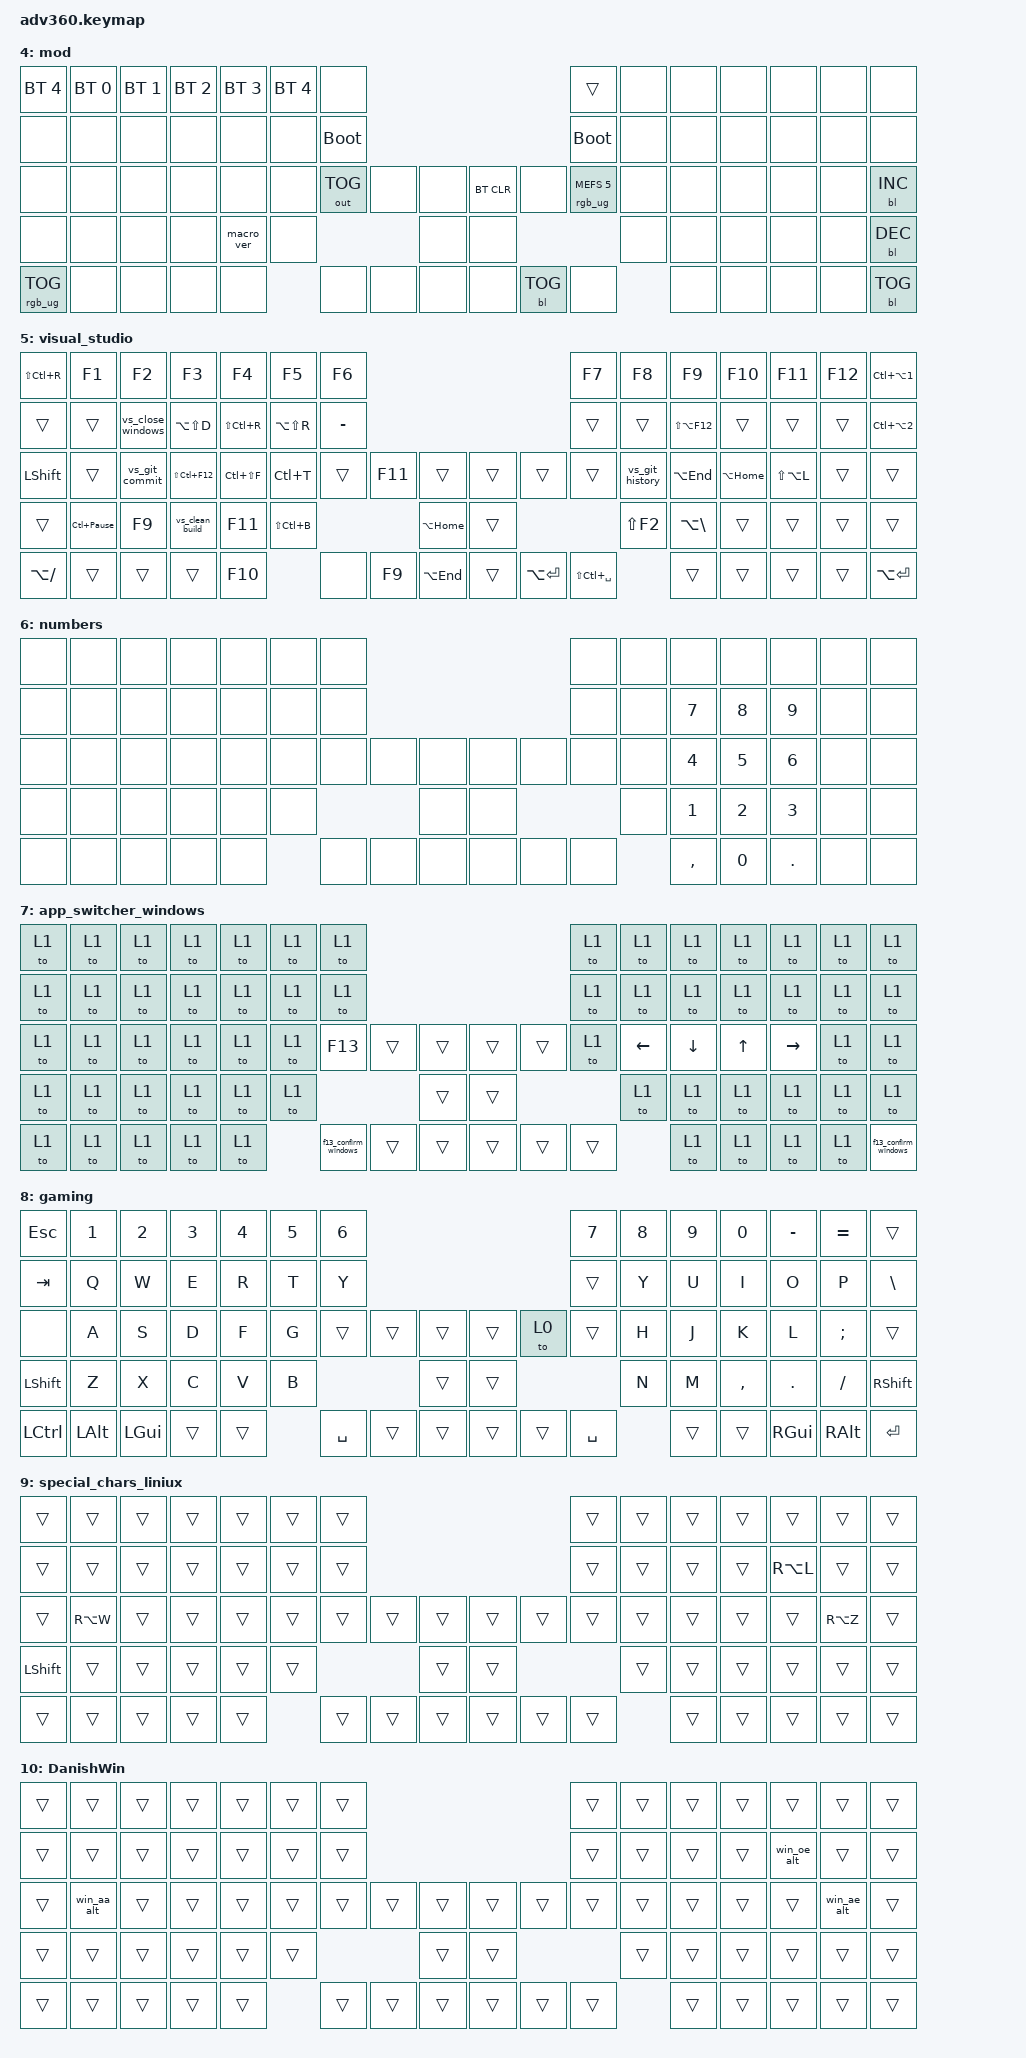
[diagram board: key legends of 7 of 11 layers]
#include <dt-bindings/zmk/mouse.h>
#include <behaviors.dtsi>
#include <dt-bindings/zmk/backlight.h>
#include <dt-bindings/zmk/bt.h>
#include <dt-bindings/zmk/keys.h>
#include <dt-bindings/zmk/outputs.h>
#include <dt-bindings/zmk/pointing.h>
#include <dt-bindings/zmk/rgb.h>

&mt { tapping-term-ms = <225>; };

/ {
    behaviors {
        #include "macros.dtsi"
      #include "version.dtsi"
      #ifndef VERSION_MACRO

        macro_ver: macro_ver {
            compatible = "zmk,behavior-macro";
            label = "macro_version";
            #binding-cells = <0>;
            bindings = <&kp RET>;
        };

        #endif

        as_ht: autoshift_hold_tap {
            compatible = "zmk,behavior-hold-tap";
            label = "AUTOSHIFT_HOLD_TAP";
            #binding-cells = <2>;
            tapping-term-ms = <200>;
            bindings = <&shifted>, <&kp>;

            quick-tap-ms = <175>;
            flavor = "tap-preferred";
        };

        shifted: macro_shifted_kp {
            #binding-cells = <1>;
            label = "MACRO_SHIFTED_KP";
            compatible = "zmk,behavior-macro-one-param";
            bindings =
                <&macro_press>,
                <&kp LSHFT &macro_param_1to1>,
                <&macro_tap>,
                <&kp MACRO_PLACEHOLDER>,
                <&macro_release>,
                <&kp LSHFT>;
        };

        as: autoshift {
            compatible = "zmk,behavior-macro-one-param";
            #binding-cells = <1>;
            label = "AUTOSHIFT_KP";
            bindings =
                <&macro_press>,
                <&macro_param_1to1 &macro_param_1to2 &as_ht MACRO_PLACEHOLDER MACRO_PLACEHOLDER>,
                <&macro_pause_for_release>,
                <&macro_release>,
                <&macro_param_1to1 &macro_param_1to2 &as_ht MACRO_PLACEHOLDER MACRO_PLACEHOLDER>;
        };

        smiley: smiley {
            compatible = "zmk,behavior-macro";
            #binding-cells = <0>;
            bindings = <&kp COLON &kp MINUS &kp RPAR &kp LC(Z) &kp SPACE &kp LC(Z)>;
            label = "SMILEY";
        };

        vs_close_windows: vs_close_windows {
            compatible = "zmk,behavior-macro";
            #binding-cells = <0>;
            bindings = <&kp LA(W) &kp L>;
            label = "VS_CLOSE_WINDOWS";
        };

        vs_git_commit: vs_git_commit {
            compatible = "zmk,behavior-macro";
            #binding-cells = <0>;
            bindings = <&kp LA(G) &kp C>;
            label = "VS_GIT_COMMIT";
        };

        vs_clean_build: vs_clean_build {
            compatible = "zmk,behavior-macro";
            #binding-cells = <0>;
            bindings = <&kp LA(B) &kp C>;
            label = "VS_CLEAN_BUILD";
        };

        vs_git_history: vs_git_history {
            compatible = "zmk,behavior-macro";
            #binding-cells = <0>;
            bindings = <&kp LA(G) &kp H>;
            label = "VS_GIT_HISTORY";
        };

        equal_lt: equal_lt {
            compatible = "zmk,behavior-macro";
            #binding-cells = <0>;
            bindings = <&kp EQUAL &kp GREATER_THAN>;
            label = "EQUAL_LT";
        };

        macro_parens: macro_parens {
            compatible = "zmk,behavior-macro";
            #binding-cells = <0>;
            bindings = <&kp LEFT_PARENTHESIS &kp RIGHT_PARENTHESIS &kp LEFT>;
            label = "MACRO_PARENS";
        };

        macro_square: macro_square {
            compatible = "zmk,behavior-macro";
            #binding-cells = <0>;
            bindings = <&kp LEFT_BRACKET &kp RIGHT_BRACKET &kp LEFT>;
            label = "MACRO_SQUARE";
        };

        macro_curly: macro_curly {
            compatible = "zmk,behavior-macro";
            #binding-cells = <0>;
            bindings = <&kp LEFT_BRACE &kp RIGHT_BRACE &kp LEFT>;
            label = "MACRO_CURLY";
        };

        macro_pointy: macro_pointy {
            compatible = "zmk,behavior-macro";
            #binding-cells = <0>;
            bindings = <&kp LESS_THAN &kp GREATER_THAN &kp LEFT>;
            label = "MACRO_POINTY";
        };

        macro_quote_pair: macro_quote_pair {
            compatible = "zmk,behavior-macro";
            #binding-cells = <0>;
            bindings = <&kp DOUBLE_QUOTES &kp DOUBLE_QUOTES &kp LEFT>;
            label = "MACRO_QUOTE_PAIR";
        };

        macro_backtick_pair: macro_backtick_pair {
            compatible = "zmk,behavior-macro";
            #binding-cells = <0>;
            bindings = <&kp GRAVE &kp GRAVE &kp LEFT>;
            label = "MACRO_BACKTICK_PAIR";
        };

        f13_switcher_mac: f13_switcher_mac {
            compatible = "zmk,behavior-macro";
            #binding-cells = <0>;
            bindings = <&kp F13 &to 0>;
            label = "F13_SWITCHER_MAC";
        };

        f13_confirm_mac: confirm_app_switch {
            compatible = "zmk,behavior-macro";
            #binding-cells = <0>;
            bindings = <&kp ENTER &to 0>;
            label = "CONFIRM_APP_SWITCH";
        };

        single_quote_pair: single_quote_pair {
            compatible = "zmk,behavior-macro";
            #binding-cells = <0>;
            bindings = <&kp SQT &kp SQT &kp LEFT>;
            label = "SINGLE_QUOTE_PAIR";
        };

        f13_app_sw_windows: f13_app_sw_windows {
            compatible = "zmk,behavior-macro";
            #binding-cells = <0>;
            bindings = <&kp F13 &to 7>;
            label = "F13_APP_SW_WINDOWS";
        };

        f13_confirm_windows: f13_confirm_windows {
            compatible = "zmk,behavior-macro";
            #binding-cells = <0>;
            bindings = <&kp ENTER &to 1>;
            label = "F13_CONFIRM_WINDOWS";
        };

        windows_oe: windows_oe {
            compatible = "zmk,behavior-macro";
            #binding-cells = <0>;
            bindings = <&kt LEFT_META &kp O &kt LEFT_META>;
            label = "WINDOWS_OE";
        };

        windows_ae: windows_ae {
            compatible = "zmk,behavior-macro";
            #binding-cells = <0>;
            bindings = <&kt LEFT_META &kp SINGLE_QUOTE &kt LEFT_META>;
            label = "WINDOWS_AE";
        };

        windows_aa: windows_aa {
            compatible = "zmk,behavior-macro";
            #binding-cells = <0>;
            bindings = <&kt LEFT_META &kp A &kt LEFT_META>;
            label = "WINDOWS_AA";
        };

        win_aa_alt: win_aa_alt {
            compatible = "zmk,behavior-macro";
            #binding-cells = <0>;
            label = "WIN_AA_ALT";
            bindings =
                <&macro_press>,
                <&kp LALT>,
                <&macro_tap>,
                <&kp KP_N0 &kp KP_N2 &kp KP_N2 &kp KP_N9>,
                <&macro_release>,
                <&kp LALT>;
        };

        win_oe_alt: win_oe_alt {
            compatible = "zmk,behavior-macro";
            #binding-cells = <0>;
            label = "WIN_OE_ALT";
            bindings =
                <&macro_press>,
                <&kp LALT>,
                <&macro_tap>,
                <&kp KP_N0 &kp KP_N2 &kp KP_N4 &kp KP_N8>,
                <&macro_release>,
                <&kp LALT>;
        };

        win_ae_alt: win_ae_alt {
            compatible = "zmk,behavior-macro";
            #binding-cells = <0>;
            label = "WIN_AE_ALT";
            bindings =
                <&macro_press>,
                <&kp LALT>,
                <&macro_tap>,
                <&kp KP_N0 &kp KP_N2 &kp KP_N3 &kp KP_N0>,
                <&macro_release>,
                <&kp LALT>;
        };

        linux_move_window: linux_move_win {
            compatible = "zmk,behavior-macro";
            #binding-cells = <0>;
            bindings =
                <&macro_press>,
                <&kp LGUI &mkp MB1>,
                <&macro_pause_for_release>,
                <&macro_release>,
                <&kp LGUI &mkp MB1>;

            label = "LINUX_MOVE_WIN";
        };

        linux_resize_window: linux_resize_window {
            compatible = "zmk,behavior-macro";
            #binding-cells = <0>;
            bindings =
                <&macro_press>,
                <&kp LGUI &mkp MB2>,
                <&macro_pause_for_release>,
                <&macro_release>,
                <&kp LGUI &mkp MB2>;

            label = "LINUX_RESIZE_WINDOW";
        };

        linux_aa: linux_aa {
            compatible = "zmk,behavior-macro";
            #binding-cells = <0>;
            bindings = <&kp LC(LS(U)) &kp E &kp NUMBER_5 &kp SPACE>;
            label = "LINUX_AA";
        };

        linux_oe: linux_oe {
            compatible = "zmk,behavior-macro";
            #binding-cells = <0>;
            bindings = <&kp LC(LS(U)) &kp F &kp N8 &kp SPACE>;
            label = "LINUX_OE";
        };

        linux_ae: linux_ae {
            compatible = "zmk,behavior-macro";
            #binding-cells = <0>;
            bindings = <&kp LS(LC(U)) &kp E &kp N6 &kp SPACE>;
            label = "LINUX_AE";
        };

        linux_hide_others: linux_hide_others {
            compatible = "zmk,behavior-macro";
            #binding-cells = <0>;
            bindings =
                <&kp LG(D)>,
                <&macro_press>,
                <&kp LALT>,
                <&macro_tap>,
                <&kp TAB>,
                <&macro_release>,
                <&kp LALT>;

            label = "LINUX_HIDE_OTHERS";
        };

        switch_to_windows: switch_to_windows {
            compatible = "zmk,behavior-macro";
            #binding-cells = <0>;
            bindings = <&out OUT_USB &to 1 &bt BT_SEL 4>;
            label = "SWITCH_TO_WINDOWS";
        };

        switch_to_linux_bt: switch_to_linux {
            compatible = "zmk,behavior-macro";
            #binding-cells = <0>;
            bindings = <&out OUT_BLE &to 0 &bt BT_SEL 0>;
            label = "SWITCH_TO_LINUX";
        };

        smiley_linux: smiley_linux {
            compatible = "zmk,behavior-macro";
            #binding-cells = <0>;
            bindings = <&kp COLON &kp MINUS &kp RPAR &kp LC(Z) &kp SPACE>;
            label = "SMILEY_LINUX";
        };

        switch_to_linux_wired: switch_to_linux_wired {
            compatible = "zmk,behavior-macro";
            #binding-cells = <0>;
            bindings = <&out OUT_USB &to 0>;
            label = "SWITCH_TO_LINUX_WIRED";
        };

        shift_caps_words: shift_caps_words {
            compatible = "zmk,behavior-tap-dance";
            label = "SHIFT_CAPS_WORDS";
            #binding-cells = <0>;
            bindings = <&kp LEFT_SHIFT>, <&caps_word>;
        };

        holdtap_tap_preferred: holdtap_tap_preferred {
            compatible = "zmk,behavior-hold-tap";
            label = "HOLDTAP_TAP_PREFERRED";
            bindings = <&kp>, <&kp>;

            #binding-cells = <2>;
            tapping-term-ms = <200>;
            flavor = "tap-preferred";
        };

        holdtap_altgr: holdtap_altgr {
            compatible = "zmk,behavior-hold-tap";
            label = "HOLDTAP_ALTGR";
            bindings = <&kp>, <&kp>;

            #binding-cells = <2>;
            tapping-term-ms = <200>;
            quick-tap-ms = <175>;
            flavor = "balanced";
            hold-trigger-on-release;
            hold-trigger-key-positions = <16 43 47>;
        };

        hml: hml {
            compatible = "zmk,behavior-hold-tap";
            label = "HML";
            bindings = <&kp>, <&kp>;

            #binding-cells = <2>;
            tapping-term-ms = <280>;
            quick-tap-ms = <175>;
            require-prior-idle-ms = <150>;
            flavor = "balanced";
            hold-trigger-on-release;
            hold-trigger-key-positions = <8 9 10 11 12 22 23 24 25 26 40 41 42 43 44 54 55 56 57 58 65 66 69 70 13 27 45 59>;
        };

        hmr: hmr {
            compatible = "zmk,behavior-hold-tap";
            label = "HMR";
            bindings = <&kp>, <&kp>;

            #binding-cells = <2>;
            tapping-term-ms = <280>;
            quick-tap-ms = <175>;
            require-prior-idle-ms = <150>;
            flavor = "balanced";
            hold-trigger-on-release;
            hold-trigger-key-positions = <1 2 3 4 5 15 16 17 18 19 29 30 31 32 33 47 48 49 50 51 65 66 70 69 0 14 28 46>;
        };

        htnr: htnr {
            compatible = "zmk,behavior-hold-tap";
            label = "HTNR";
            bindings = <&mo>, <&kp>;

            #binding-cells = <2>;
            tapping-term-ms = <280>;
            flavor = "balanced";
            hold-trigger-key-positions = <7 8 9 10 11 12 13 21 22 23 24 25 26 27 38 39 40 41 42 43 44 45 54 55 56 57 58 59 69 70 71 72 73 74 75>;
            hold-trigger-on-release;
            quick-tap-ms = <175>;
            require-prior-idle-ms = <150>;
        };

        htnl: htnl {
            compatible = "zmk,behavior-hold-tap";
            label = "HTNL";
            bindings = <&mo>, <&kp>;

            #binding-cells = <2>;
            tapping-term-ms = <280>;
            flavor = "balanced";
            hold-trigger-on-release;
            quick-tap-ms = <175>;
            require-prior-idle-ms = <150>;
            hold-trigger-key-positions = <0 1 2 3 4 5 6 14 15 16 17 18 19 20 28 29 30 31 32 33 34 35 46 47 48 49 50 51 60 61 62 63 64 65 66>;
        };

        holdtap_danish: holdtap_danish {
            compatible = "zmk,behavior-hold-tap";
            label = "HOLDTAP_DANISH";
            bindings = <&kp>, <&kp>;

            #binding-cells = <2>;
            tapping-term-ms = <200>;
            hold-trigger-key-positions = <29 45 25>;
            flavor = "balanced";
        };
    };

    macros {
    };

    keymap {
        compatible = "zmk,keymap";

        Linux {
            label = "Linux";
            bindings = <
&kp GRAVE       &kp N1  &kp N2  &kp N3    &kp N4    &kp N5  &lt 4 NUMBER_6                                                                                      &lt 4 NUMBER_7      &kp NUMBER_8  &kp NUMBER_9                           &kp NUMBER_0                               &kp MINUS  &kp EQUAL      &none
&kp TAB         &kp Q   &kp W   &kp E     &kp R     &kp T   &to 1                                                                                               &kp LG(L)           &kp Y         &kp U                                  &kp I                                      &kp O      &kp P          &kp BACKSLASH
&kp CAPSLOCK    &kp A   &kp S   &kp D     &kp F     &kp G   &kp LG(W)       &kp LS(LA(LCTRL))  &kp LS(LA(LC(LGUI)))      &switch_to_linux_wired  &to 8          &kp LC(LA(DELETE))  &kp H         &kp J                                  &kp K                                      &kp L      &kp SEMICOLON  &kp SQT
&kp LEFT_SHIFT  &kp Z   &kp X   &kp C     &kp V     &kp B                                      &bl BL_TOG                &switch_to_linux_bt                                        &kp N         &kp M                                  &kp COMMA                                  &kp DOT    &kp FSLH       &kp RIGHT_SHIFT
&kp LCTRL       &mo 6   &none   &kp LGUI  &kp LALT          &mo 3           &kp RA(O)          &kp LCMD                  &switch_to_windows      &kp BACKSPACE  &kp SPACE                         &holdtap_altgr RIGHT_ALT LEFT_BRACKET  &holdtap_tap_preferred LGUI RIGHT_BRACKET  &none      &none          &mt RCTRL ENTER
            >;
        };

        windows {
            label = "Windows";
            bindings = <
&kp GRAVE       &kp N1  &kp N2  &kp N3    &kp N4        &kp N5  &lt 4 NUMBER_6                                                                                           &lt 4 NUMBER_7      &kp NUMBER_8  &kp NUMBER_9                           &kp NUMBER_0                             &kp MINUS  &kp EQUAL      &none
&kp TAB         &kp Q   &kp W   &kp E     &kp R         &kp T   &to 0                                                                                                    &kp LG(L)           &kp Y         &kp U                                  &kp I                                    &kp O      &kp P          &kp BACKSLASH
&kp ESC         &kp A   &kp S   &kp D     &kp F         &kp G   &f13_app_sw_windows  &kp LS(LA(LCTRL))  &kp LS(LA(LC(LGUI)))      &switch_to_linux_wired  &to 8          &kp LC(LA(DELETE))  &kp H         &kp J                                  &kp K                                    &kp L      &kp SEMICOLON  &kp SQT
&kp LEFT_SHIFT  &kp Z   &kp X   &kp C     &kp V         &kp B                                           &none                     &switch_to_linux_bt                                        &kp N         &kp M                                  &kp COMMA                                &kp DOT    &kp FSLH       &kp RIGHT_SHIFT
&kp LCTRL       &mo 6   &none   &kp LWIN  &kp LEFT_ALT          &mo 2                &mo 5              &kp LCMD                  &switch_to_windows      &kp BACKSPACE  &kp SPACE                         &holdtap_altgr RIGHT_ALT LEFT_BRACKET  &holdtap_danish RIGHT_GUI RIGHT_BRACKET  &mo 10     &kp RCTRL      &kp ENTER
            >;
        };

        fn_windows {
            bindings = <
&kp LA(LC(LG(Z)))  &kp F1      &kp F2      &kp F3      &kp F4          &kp F5     &kp F6                                                                              &kp F7           &kp F8             &kp F9         &kp F10        &kp F11            &kp F12        &kp DELETE
&kp LA(LC(LG(Y)))  &kp LA(F4)  &kp LC(F4)  &none       &kp LC(R)       &kp LC(T)  &kp LG(LC(LA(N5)))                                                                  &kp PRINTSCREEN  &none              &none          &kp LC(LS(I))  &none              &kp LS(LC(P))  &smiley
&none              &kp LC(A)   &none       &kp DELETE  &none           &none      &kp LG(LC(LA(N6)))  &trans  &trans             &kp LG(LC(LEFT))  &kp LC(LG(RIGHT))  &none            &kp LEFT           &kp DOWN       &kp UP_ARROW   &kp RIGHT          &none          &none
&kp LEFT_SHIFT     &kp LC(Z)   &kp LC(X)   &kp LC(C)   &kp LS(INSERT)  &kp LG(V)                              &trans             &trans                                                &mt HOME LC(LEFT)  &kp PAGE_DOWN  &kp PG_UP      &mt END LC(RIGHT)  &none          &macro_quote_pair
&mkp MB4           &mkp MB5    &mkp RCLK   &mkp MCLK   &mkp LCLK                  &none               &none   &kp LC(LS(M))      &to 0             &kp DELETE         &kp LA(SPACE)                       &macro_parens  &macro_square  &macro_curly       &macro_pointy  &single_quote_pair
            >;
        };

        fn_linux {
            bindings = <
&linux_move_window    &mt F1 LA(N1)  &mt F2 LA(N2)  &mt F3 LA(N3)   &mt F4 LA(N4)   &mt F5 LA(N5)  &mt F6 LA(N6)                                                                       &mt F7 LA(N7)    &mt F8 LA(N8)      &mt F9 LA(N9)  &kp F10        &kp F11             &kp F12        &kp DELETE
&linux_resize_window  &kp LG(Q)      &kp LC(F4)     &kp LG(T)       &kp LC(R)       &kp LC(T)      &kp LG(LC(LA(N5)))                                                                  &kp PRINTSCREEN  &none              &none          &kp LC(LS(I))  &linux_hide_others  &kp LS(LC(P))  &smiley_linux
&none                 &kp LC(A)      &none          &kp DELETE      &none           &kp LG(SPACE)  &kp LG(LC(LA(N6)))  &trans  &trans             &kp LG(LC(LEFT))  &kp LC(LG(RIGHT))  &none            &kp LEFT           &kp DOWN       &kp UP_ARROW   &kp RIGHT           &none          &none
&kp LEFT_SHIFT        &kp LC(Z)      &kp LC(X)      &kp LC(INSERT)  &kp LS(INSERT)  &kp LG(V)                                  &trans             &trans                                                &mt HOME LC(LEFT)  &kp PAGE_DOWN  &kp PG_UP      &mt END LC(RIGHT)   &none          &macro_quote_pair
&mkp MB4              &mkp MB5       &mkp RCLK      &mkp MCLK       &mkp LCLK                      &none               &none   &kp LC(LS(M))      &to 0             &kp DELETE         &kp LGUI                            &kp LG(H)      &none          &none               &none          &to 8
            >;
        };

        mod {
            bindings = <
&bt BT_SEL 4     &bt BT_SEL 0  &bt BT_SEL 1  &bt BT_SEL 2  &bt BT_SEL 3  &bt BT_SEL 4  &none                                                   &trans                  &none  &none  &none  &none  &none  &none
&none            &none         &none         &none         &none         &none         &bootloader                                             &bootloader             &none  &none  &none  &none  &none  &none
&none            &none         &none         &none         &none         &none         &out OUT_TOG  &none  &none      &bt BT_CLR  &none       &rgb_ug RGB_MEFS_CMD 5  &none  &none  &none  &none  &none  &bl BL_INC
&none            &none         &none         &none         &macro_ver    &none                              &none      &none                                           &none  &none  &none  &none  &none  &bl BL_DEC
&rgb_ug RGB_TOG  &none         &none         &none         &none                       &none         &none  &none      &none       &bl BL_TOG  &none                          &none  &none  &none  &none  &bl BL_TOG
            >;
        };

        visual_studio {
            bindings = <
&kp LS(LC(R))  &kp F1               &kp F2             &kp F3           &kp F4         &kp F5         &kp F6                                                       &kp F7             &kp F8           &kp F9           &kp F10       &kp F11        &kp F12  &kp LC(LA(N1))
&trans         &trans               &vs_close_windows  &kp LA(LS(D))    &kp LS(LC(R))  &kp LA(LS(R))  &kp MINUS                                                    &trans             &trans           &kp LS(LA(F12))  &trans        &trans         &trans   &kp LC(LA(N2))
&kp LSHFT      &trans               &vs_git_commit     &kp LS(LC(F12))  &kp LC(LS(F))  &kp LC(T)      &trans     &kp F11  &trans            &trans  &trans         &trans             &vs_git_history  &kp LA(END)      &kp LA(HOME)  &kp LS(LA(L))  &trans   &trans
&trans         &kp LC(PAUSE_BREAK)  &kp F9             &vs_clean_build  &kp F11        &kp LS(LC(B))                      &kp LA(HOME)      &trans                                    &kp LS(F2)       &kp LA(BSLH)     &trans        &trans         &trans   &trans
&kp LA(SLASH)  &trans               &trans             &trans           &kp F10                       &none      &kp F9   &kp LA(END)       &trans  &kp LA(ENTER)  &kp LS(LC(SPACE))                   &trans           &trans        &trans         &trans   &kp LA(ENTER)
            >;
        };

        numbers {
            bindings = <
&none  &none  &none  &none  &none  &none  &none                                  &none  &none  &none      &none   &none    &none  &none
&none  &none  &none  &none  &none  &none  &none                                  &none  &none  &kp N7     &kp N8  &kp N9   &none  &none
&none  &none  &none  &none  &none  &none  &none  &none  &none      &none  &none  &none  &none  &kp N4     &kp N5  &kp N6   &none  &none
&none  &none  &none  &none  &none  &none                &none      &none                &none  &kp N1     &kp N2  &kp N3   &none  &none
&none  &none  &none  &none  &none         &none  &none  &none      &none  &none  &none         &kp COMMA  &kp N0  &kp DOT  &none  &none
            >;
        };

        app_switcher_windows {
            bindings = <
&to 1  &to 1  &to 1  &to 1  &to 1  &to 1  &to 1                                                     &to 1   &to 1     &to 1     &to 1         &to 1      &to 1  &to 1
&to 1  &to 1  &to 1  &to 1  &to 1  &to 1  &to 1                                                     &to 1   &to 1     &to 1     &to 1         &to 1      &to 1  &to 1
&to 1  &to 1  &to 1  &to 1  &to 1  &to 1  &kp F13               &trans  &trans      &trans  &trans  &to 1   &kp LEFT  &kp DOWN  &kp UP_ARROW  &kp RIGHT  &to 1  &to 1
&to 1  &to 1  &to 1  &to 1  &to 1  &to 1                                &trans      &trans                  &to 1     &to 1     &to 1         &to 1      &to 1  &to 1
&to 1  &to 1  &to 1  &to 1  &to 1         &f13_confirm_windows  &trans  &trans      &trans  &trans  &trans            &to 1     &to 1         &to 1      &to 1  &f13_confirm_windows
            >;
        };

        gaming {
            bindings = <
&kp ESC    &kp N1    &kp N2    &kp N3  &kp N4  &kp N5  &kp N6                                         &kp N7     &kp N8  &kp N9  &kp N0     &kp MINUS  &kp EQUAL  &trans
&kp TAB    &kp Q     &kp W     &kp E   &kp R   &kp T   &kp Y                                          &trans     &kp Y   &kp U   &kp I      &kp O      &kp P      &kp BSLH
&none      &kp A     &kp S     &kp D   &kp F   &kp G   &trans     &trans  &trans      &trans  &to 0   &trans     &kp H   &kp J   &kp K      &kp L      &kp SEMI   &trans
&kp LSHFT  &kp Z     &kp X     &kp C   &kp V   &kp B                      &trans      &trans                     &kp N   &kp M   &kp COMMA  &kp DOT    &kp FSLH   &kp RSHFT
&kp LCTRL  &kp LALT  &kp LGUI  &trans  &trans          &kp SPACE  &trans  &trans      &trans  &trans  &kp SPACE          &trans  &trans     &kp RGUI   &kp RALT   &kp ENTER
            >;
        };

        special_chars_liniux {
            bindings = <
&trans          &trans     &trans  &trans  &trans  &trans  &trans                                      &trans  &trans  &trans  &trans  &trans     &trans     &trans
&trans          &trans     &trans  &trans  &trans  &trans  &trans                                      &trans  &trans  &trans  &trans  &kp RA(L)  &trans     &trans
&trans          &kp RA(W)  &trans  &trans  &trans  &trans  &trans  &trans  &trans      &trans  &trans  &trans  &trans  &trans  &trans  &trans     &kp RA(Z)  &trans
&kp LEFT_SHIFT  &trans     &trans  &trans  &trans  &trans                  &trans      &trans                  &trans  &trans  &trans  &trans     &trans     &trans
&trans          &trans     &trans  &trans  &trans          &trans  &trans  &trans      &trans  &trans  &trans          &trans  &trans  &trans     &trans     &trans
            >;
        };

        danish_win {
            label = "DanishWin";
            bindings = <
&trans  &trans       &trans  &trans  &trans  &trans  &trans                                      &trans  &trans  &trans  &trans  &trans       &trans       &trans
&trans  &trans       &trans  &trans  &trans  &trans  &trans                                      &trans  &trans  &trans  &trans  &win_oe_alt  &trans       &trans
&trans  &win_aa_alt  &trans  &trans  &trans  &trans  &trans  &trans  &trans      &trans  &trans  &trans  &trans  &trans  &trans  &trans       &win_ae_alt  &trans
&trans  &trans       &trans  &trans  &trans  &trans                  &trans      &trans                  &trans  &trans  &trans  &trans       &trans       &trans
&trans  &trans       &trans  &trans  &trans          &trans  &trans  &trans      &trans  &trans  &trans          &trans  &trans  &trans       &trans       &trans
            >;
        };
    };
};
